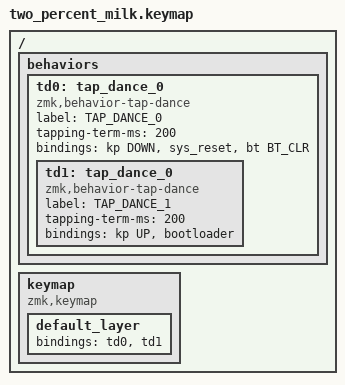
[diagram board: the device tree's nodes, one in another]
/*
 * Copyright (c) 2022 The ZMK Contributors
 *
 *
 * SPDX-License-Identifier: MIT
 */

#include <behaviors.dtsi>
#include <dt-bindings/zmk/keys.h>
#include <dt-bindings/zmk/bt.h>
#include <dt-bindings/zmk/outputs.h>

/ {
behaviors {
        td0: tap_dance_0 {
            compatible = "zmk,behavior-tap-dance";
            label = "TAP_DANCE_0";
            #binding-cells = <0>;
            tapping-term-ms = <200>;
            bindings = <&kp DOWN>, <&sys_reset>, <&bt BT_CLR>;
        
        td1: tap_dance_0 {
            compatible = "zmk,behavior-tap-dance";
            label = "TAP_DANCE_1";
            #binding-cells = <0>;
            tapping-term-ms = <200>;
            bindings = <&kp UP>, <&bootloader>;
        	};    
    	};
    };

    keymap {
        compatible = "zmk,keymap";

        default_layer {
            bindings = <
                &td0
                &td1
            >;
        };
    };
};
